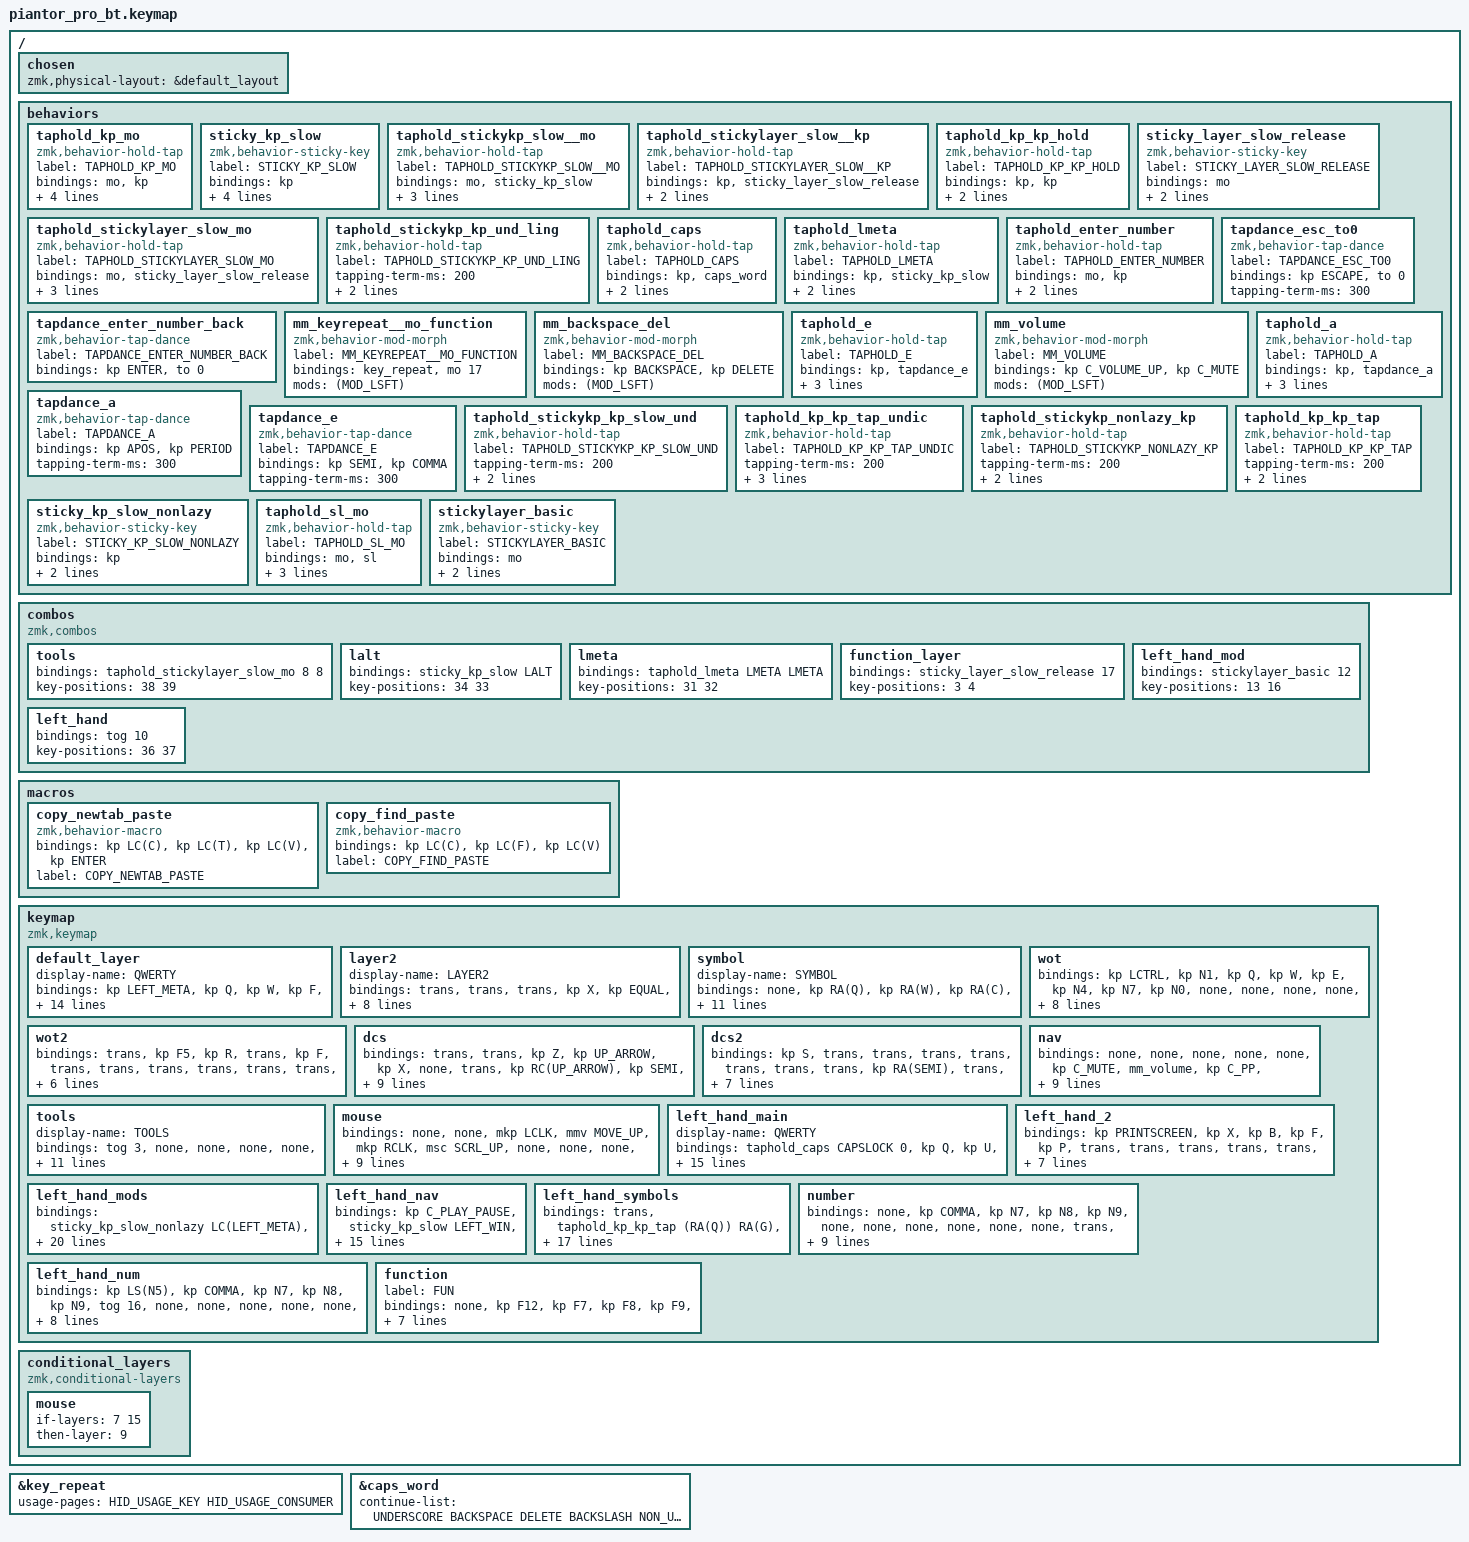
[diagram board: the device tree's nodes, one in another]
/*
 * Copyright (c) 2020 The ZMK Contributors
 *
 * SPDX-License-Identifier: MIT
 */

#include <behaviors.dtsi>
#include <dt-bindings/zmk/bt.h>
#include <dt-bindings/zmk/keys.h>
#include <dt-bindings/zmk/outputs.h>
#include <dt-bindings/zmk/pointing.h>
#include <dt-bindings/zmk/rgb.h>

&key_repeat { usage-pages = <HID_USAGE_KEY HID_USAGE_CONSUMER>; };

&caps_word { continue-list = <UNDERSCORE BACKSPACE DELETE BACKSLASH NON_US_BACKSLASH MINUS EQUAL APOSTROPHE LEFT_BRACKET RIGHT_BRACKET NUMBER_0 SEMICOLON>; };

/ {
    chosen { zmk,physical-layout = &default_layout; };
};

/ {
    behaviors {
        taphold_kp_mo: taphold_kp_mo {
            compatible = "zmk,behavior-hold-tap";
            label = "TAPHOLD_KP_MO";
            bindings = <&mo>, <&kp>;

            #binding-cells = <2>;
            hold-while-undecided;
            hold-trigger-on-release;
            flavor = "balanced";
            tapping-term-ms = <200>;
        };

        sticky_kp_slow: sticky_kp_slow {
            compatible = "zmk,behavior-sticky-key";
            label = "STICKY_KP_SLOW";
            bindings = <&kp>;
            #binding-cells = <1>;
            release-after-ms = <2000>;
            lazy;
            ignore-modifiers;
            quick-release;
        };

        taphold_stickykp_slow__mo: taphold_stickykp_slow__mo {
            compatible = "zmk,behavior-hold-tap";
            label = "TAPHOLD_STICKYKP_SLOW__MO";
            bindings = <&mo>, <&sticky_kp_slow>;

            #binding-cells = <2>;
            hold-while-undecided;
            flavor = "hold-preferred";
            tapping-term-ms = <200>;
        };

        taphold_stickylayer_slow__kp: taphold_stickylayer_slow__kp {
            compatible = "zmk,behavior-hold-tap";
            label = "TAPHOLD_STICKYLAYER_SLOW__KP";
            bindings = <&kp>, <&sticky_layer_slow_release>;

            #binding-cells = <2>;
            tapping-term-ms = <200>;
            flavor = "balanced";
        };

        taphold_kp_kp_hold: taphold_kp_kp_hold {
            compatible = "zmk,behavior-hold-tap";
            label = "TAPHOLD_KP_KP_HOLD";
            bindings = <&kp>, <&kp>;

            #binding-cells = <2>;
            flavor = "hold-preferred";
            tapping-term-ms = <230>;
        };

        sticky_layer_slow_release: sticky_layer_slow_release {
            compatible = "zmk,behavior-sticky-key";
            label = "STICKY_LAYER_SLOW_RELEASE";
            bindings = <&mo>;
            #binding-cells = <1>;
            release-after-ms = <1000>;
            ignore-modifiers;
        };

        taphold_stickylayer_slow_mo: taphold_stickylayer_slow_mo {
            compatible = "zmk,behavior-hold-tap";
            label = "TAPHOLD_STICKYLAYER_SLOW_MO";
            bindings = <&mo>, <&sticky_layer_slow_release>;

            #binding-cells = <2>;
            flavor = "balanced";
            hold-while-undecided;
            tapping-term-ms = <200>;
        };

        taphold_stickykp_kp_und_ling: taphold_stickykp_kp_und_ling {
            compatible = "zmk,behavior-hold-tap";
            label = "TAPHOLD_STICKYKP_KP_UND_LING";
            #binding-cells = <2>;
            tapping-term-ms = <200>;
            bindings = <&kp>, <&sticky_kp_slow>;

            hold-while-undecided-linger;
        };

        taphold_caps: taphold_caps {
            compatible = "zmk,behavior-hold-tap";
            label = "TAPHOLD_CAPS";
            bindings = <&kp>, <&caps_word>;

            #binding-cells = <2>;
            tapping-term-ms = <200>;
            flavor = "tap-preferred";
        };

        taphold_lmeta: taphold_lmeta {
            compatible = "zmk,behavior-hold-tap";
            label = "TAPHOLD_LMETA";
            bindings = <&kp>, <&sticky_kp_slow>;

            #binding-cells = <2>;
            tapping-term-ms = <200>;
            flavor = "balanced";
        };

        taphold_enter_number: taphold_enter_number {
            compatible = "zmk,behavior-hold-tap";
            label = "TAPHOLD_ENTER_NUMBER";
            bindings = <&mo>, <&kp>;

            #binding-cells = <2>;
            tapping-term-ms = <200>;
            flavor = "balanced";
        };

        tapdance_enter_number_back: tapdance_enter_number_back {
            compatible = "zmk,behavior-tap-dance";
            label = "TAPDANCE_ENTER_NUMBER_BACK";
            #binding-cells = <0>;
            bindings = <&kp ENTER>, <&to 0>;
        };

        mm_keyrepeat__mo_function: mm_keyrepeat__mo_function {
            compatible = "zmk,behavior-mod-morph";
            label = "MM_KEYREPEAT__MO_FUNCTION";
            bindings = <&key_repeat>, <&mo 17>;

            #binding-cells = <0>;
            mods = <(MOD_LSFT)>;
        };

        mm_backspace_del: mm_backspace_del {
            compatible = "zmk,behavior-mod-morph";
            label = "MM_BACKSPACE_DEL";
            bindings = <&kp BACKSPACE>, <&kp DELETE>;

            #binding-cells = <0>;
            mods = <(MOD_LSFT)>;
        };

        tapdance_esc_to0: tapdance_esc_to0 {
            compatible = "zmk,behavior-tap-dance";
            label = "TAPDANCE_ESC_TO0";
            #binding-cells = <0>;
            bindings = <&kp ESCAPE>, <&to 0>;

            tapping-term-ms = <300>;
        };

        taphold_e: taphold_e {
            compatible = "zmk,behavior-hold-tap";
            label = "TAPHOLD_E";
            bindings = <&kp>, <&tapdance_e>;

            #binding-cells = <2>;
            flavor = "tap-preferred";
            tapping-term-ms = <170>;
            quick-tap-ms = <169>;
        };

        mm_volume: mm_volume {
            compatible = "zmk,behavior-mod-morph";
            label = "MM_VOLUME";
            bindings = <&kp C_VOLUME_UP>, <&kp C_MUTE>;

            #binding-cells = <0>;
            mods = <(MOD_LSFT)>;
        };

        tapdance_a: tapdance_a {
            compatible = "zmk,behavior-tap-dance";
            label = "TAPDANCE_A";
            #binding-cells = <0>;
            bindings = <&kp APOS>, <&kp PERIOD>;

            tapping-term-ms = <300>;
        };

        tapdance_e: tapdance_e {
            compatible = "zmk,behavior-tap-dance";
            label = "TAPDANCE_E";
            #binding-cells = <0>;
            bindings = <&kp SEMI>, <&kp COMMA>;

            tapping-term-ms = <300>;
        };

        taphold_a: taphold_a {
            compatible = "zmk,behavior-hold-tap";
            label = "TAPHOLD_A";
            bindings = <&kp>, <&tapdance_a>;

            #binding-cells = <2>;
            flavor = "tap-preferred";
            tapping-term-ms = <170>;
            quick-tap-ms = <169>;
        };

        taphold_stickykp_kp_slow_und: taphold_stickykp_kp_slow_und {
            compatible = "zmk,behavior-hold-tap";
            label = "TAPHOLD_STICKYKP_KP_SLOW_UND";
            #binding-cells = <2>;
            tapping-term-ms = <200>;
            bindings = <&kp>, <&sticky_kp_slow>;

            hold-while-undecided;
        };

        taphold_kp_kp_tap_undic: taphold_kp_kp_tap_undic {
            compatible = "zmk,behavior-hold-tap";
            label = "TAPHOLD_KP_KP_TAP_UNDIC";
            #binding-cells = <2>;
            tapping-term-ms = <200>;
            bindings = <&kp>, <&kp>;

            hold-while-undecided;
            flavor = "tap-preferred";
        };

        taphold_stickykp_nonlazy_kp: taphold_stickykp_nonlazy_kp {
            compatible = "zmk,behavior-hold-tap";
            label = "TAPHOLD_STICKYKP_NONLAZY_KP";
            #binding-cells = <2>;
            tapping-term-ms = <200>;
            bindings = <&kp>, <&sticky_kp_slow_nonlazy>;

            flavor = "tap-preferred";
        };

        taphold_kp_kp_tap: taphold_kp_kp_tap {
            compatible = "zmk,behavior-hold-tap";
            label = "TAPHOLD_KP_KP_TAP";
            #binding-cells = <2>;
            tapping-term-ms = <200>;
            bindings = <&kp>, <&kp>;

            flavor = "tap-preferred";
        };

        sticky_kp_slow_nonlazy: sticky_kp_slow_nonlazy {
            compatible = "zmk,behavior-sticky-key";
            label = "STICKY_KP_SLOW_NONLAZY";
            bindings = <&kp>;
            #binding-cells = <1>;
            release-after-ms = <2000>;
            ignore-modifiers;
        };

        taphold_sl_mo: taphold_sl_mo {
            compatible = "zmk,behavior-hold-tap";
            label = "TAPHOLD_SL_MO";
            bindings = <&mo>, <&sl>;

            #binding-cells = <2>;
            flavor = "balanced";
            hold-while-undecided;
            tapping-term-ms = <200>;
        };

        stickylayer_basic: stickylayer_basic {
            compatible = "zmk,behavior-sticky-key";
            label = "STICKYLAYER_BASIC";
            bindings = <&mo>;
            #binding-cells = <1>;
            release-after-ms = <2000>;
            quick-release;
        };
    };

    combos {
        compatible = "zmk,combos";

        tools {
            bindings = <&taphold_stickylayer_slow_mo 8 8>;
            key-positions = <38 39>;
        };

        lalt {
            bindings = <&sticky_kp_slow LALT>;
            key-positions = <34 33>;
        };

        lmeta {
            bindings = <&taphold_lmeta LMETA LMETA>;
            key-positions = <31 32>;
        };

        function_layer {
            bindings = <&sticky_layer_slow_release 17>;
            key-positions = <3 4>;
        };

        left_hand_mod {
            bindings = <&stickylayer_basic 12>;
            key-positions = <13 16>;
        };

        left_hand {
            bindings = <&tog 10>;
            key-positions = <36 37>;
        };
    };

    macros {
        copy_newtab_paste: copy_newtab_paste {
            compatible = "zmk,behavior-macro";
            #binding-cells = <0>;
            bindings = <&kp LC(C) &kp LC(T) &kp LC(V) &kp ENTER>;
            label = "COPY_NEWTAB_PASTE";
        };

        copy_find_paste: copy_find_paste {
            compatible = "zmk,behavior-macro";
            #binding-cells = <0>;
            bindings = <&kp LC(C) &kp LC(F) &kp LC(V)>;
            label = "COPY_FIND_PASTE";
        };
    };

    keymap {
        compatible = "zmk,keymap";

        default_layer {
            display-name = "QWERTY";

            // --------------------------------------------------------------------------------
            // |  TAB |  Q  |  W  |  E  |  R  |  T  |  Y  |  U   |  I  |  O  |  P  | BSPC |
            // | CTRL |  A  |  S  |  D  |  F  |  G  |  H  |  J   |  K  |  L  |  ;  |  '   |
            // | SHFT |  Z  |  X  |  C  |  V  |  B  |  N  |  M   |  ,  |  .  |  /  | ESC  |
            //                    | GUI | LWR | SPC | ENT | RSE  | ALT |

            bindings = <
&kp LEFT_META  &kp Q  &kp W  &kp F  &kp P  &kp B  &kp J  &kp L  &kp O  &kp U  &kp DEL  &kp PRINTSCREEN  &mm_backspace_del  &kp K  &kp R  &kp S  &kp T  &kp G  &kp M  &kp N  &kp E  &kp I  &kp A  &kp TAB  &taphold_kp_kp_hold LCTRL ESCAPE  &kp Z  &kp Y  &kp C  &kp D  &kp V  &kp X  &kp H  &taphold_e COMMA SEMI  &taphold_a PERIOD APOS  &kp SLASH  &taphold_caps CAPSLOCK LGUI  &taphold_stickykp_slow__mo 7 LCTRL  &taphold_kp_mo 2 SPACE  &taphold_stickykp_kp_und_ling LSHIFT LSHIFT  &mm_keyrepeat__mo_function  &taphold_stickylayer_slow_mo 1 1  &taphold_enter_number 15 ENTER
            >;
        };

        layer2 {
            display-name = "LAYER2";

            // -----------------------------------------------------------------------------------------
            // |  TAB |  !  |  @  |  #  |  $  |  %  |  ^  |  &  |  *  |  (  |  )  | BSPC |
            // | CTRL | HUD | HUI |     |     |     |  -  |  =  |  [  |  ]  |  \  |  `   |
            // | SHFT |     |     |     |     |     |  _  |  +  |  {  |  }  | "|" |  ~   |
            //                    | GUI |     | SPC | ENT |     | ALT |

            bindings = <
&trans  &trans  &trans  &kp X  &kp EQUAL  &trans  &trans  &trans  &kp N0  &kp MINUS  &trans  &trans  &trans  &trans  &trans  &trans  &kp J  &kp RIGHT_BRACKET  &trans  &trans  &trans  &trans  &trans  &kp NON_US_BACKSLASH  &trans  &trans  &trans  &kp V  &kp B  &trans  &trans  &trans  &kp LEFT_BRACKET  &kp BACKSLASH  &trans  &trans  &trans  &trans  &trans  &trans  &trans  &trans
            >;
        };

        symbol {
            display-name = "SYMBOL";

            // -----------------------------------------------------------------------------------------
            // |  TAB |  1  |  2  |  3  |  4  |  5    |  6  |  7  |  8  |  9  |  0  | BSPC |
            // | CTRL | BT1 | BT2 | BT3 | BT4 | BT5   | LFT | DWN |  UP | RGT |     |      |
            // | SHFT | BTCR| RGB | RST | BOOT| Unlock|     |     |     |     |     |      |
            //                    | GUI |     | SPC   | ENT |     | ALT |

            bindings = <
&none  &kp RA(Q)  &kp RA(W)  &kp RA(C)  &kp RA(N7)  &none  &none  &kp LS(N9)  &kp RA(N)  &kp RA(Z)  &kp RA(G)  &none  &trans  &kp RA(NUMBER_1)  &kp LS(NUMBER_4)  &kp LS(N7)  &kp RA(COMMA)  &kp LS(NUMBER_1)  &kp LS(NUMBER_2)  &kp LS(N8)  &kp RA(B)  &kp RA(NON_US_BACKSLASH)  &kp RA(F)  &none  &none  &kp RA(NUMBER_3)  &kp RA(SEMI)  &kp RA(X)  &kp RA(V)  &none  &none  &kp LS(NUMBER_6)  &kp RA(SLASH)  &kp LS(NUMBER_3)  &kp LS(N5)  &none  &trans  &trans  &trans  &trans  &trans  &trans
            >;
        };

        wot {
            bindings = <
&kp LCTRL  &kp N1  &kp Q  &kp W  &kp E  &kp N4  &kp N7  &kp N0  &none  &none  &none  &none  &kp TAB  &kp N2  &kp A  &kp S  &kp D  &kp N5  &kp N8  &none  &none  &none  &none  &none  &tapdance_esc_to0  &kp N3  &kp X  &kp C  &kp V  &kp N6  &kp N9  &none  &none  &none  &none  &none  &mo 4  &kp SPACE  &taphold_kp_kp_hold LEFT_SHIFT ENTER  &none  &mo 0  &to 0
            >;

            label = "WOT";
        };

        wot2 {
            bindings = <
&trans  &kp F5  &kp R  &trans  &kp F  &trans  &trans  &trans  &trans  &trans  &trans  &trans  &kp F6  &kp F7  &trans  &trans  &trans  &trans  &trans  &trans  &trans  &trans  &trans  &trans  &trans  &kp F8  &kp Y  &trans  &trans  &trans  &trans  &trans  &trans  &trans  &trans  &trans  &trans  &trans  &trans  &trans  &trans  &trans
            >;
        };

        dcs {
            bindings = <
&trans  &trans  &kp Z  &kp UP_ARROW  &kp X  &none  &trans  &kp RC(UP_ARROW)  &kp SEMI  &kp RC(DOWN)  &trans  &kp BACKSLASH  &trans  &taphold_kp_kp_hold (LS(B)) LC(B)  &kp LEFT_ARROW  &kp DOWN  &kp RIGHT  &kp NUMBER_3  &trans  &kp COMMA  &kp PERIOD  &kp SLASH  &trans  &trans  &tapdance_esc_to0  &trans  &kp RS(PAGE_DOWN)  &kp LA(C)  &kp RS(PG_UP)  &none  &trans  &kp RC(LEFT)  &kp C  &kp RC(RIGHT)  &trans  &trans  &kp SPACE  &trans  &kp RA(SPACE)  &trans  &mo 6  &kp ENTER
            >;
        };

        dcs2 {
            bindings = <
&kp S  &trans  &trans  &trans  &trans  &trans  &trans  &trans  &kp RA(SEMI)  &trans  &trans  &kp LS(LC(F))  &kp RS(HOME)  &trans  &trans  &trans  &trans  &kp NUMBER_4  &trans  &kp RA(COMMA)  &kp RA(PERIOD)  &kp RA(SLASH)  &trans  &kp G  &kp RS(END)  &trans  &trans  &trans  &trans  &trans  &trans  &trans  &trans  &trans  &trans  &trans  &trans  &trans  &trans  &trans  &trans  &trans
            >;
        };

        nav {
            bindings = <
&none  &none  &none  &none  &none  &kp C_MUTE  &mm_volume  &kp C_PP  &kp C_PREVIOUS  &kp C_NEXT  &none  &none  &trans  &kp LGUI  &kp LALT  &kp LCTRL  &kp LSHFT  &none  &kp LEFT  &kp DOWN  &kp UP  &kp RIGHT  &kp PG_UP  &none  &tapdance_esc_to0  &none  &none  &none  &sticky_kp_slow LA(LC(LMETA))  &none  &kp C_VOLUME_DOWN  &kp HOME  &kp END  &kp PERIOD  &kp PAGE_DOWN  &none  &to 0  &trans  &trans  &trans  &trans  &trans
            >;

            label = "NAV";
        };

        tools {
            display-name = "TOOLS";
            bindings = <
&tog 3  &none  &none  &none  &none  &bt BT_CLR  &none  &rgb_ug RGB_TOG  &rgb_ug RGB_EFF  &rgb_ug RGB_BRD  &rgb_ug RGB_BRI  &none  &tog 5  &bt BT_SEL 0  &bt BT_SEL 1  &bt BT_SEL 2  &bt BT_SEL 3  &bt BT_SEL 4  &none  &kp C_PP  &kp C_PREVIOUS  &kp K_NEXT  &none  &none  &none  &studio_unlock  &none  &none  &out OUT_TOG  &none  &none  &rgb_ug RGB_HUD  &rgb_ug RGB_HUI  &rgb_ug RGB_SAD  &rgb_ug RGB_SAI  &rgb_ug RGB_COLOR_HSB(0,0,100)  &trans  &trans  &trans  &trans  &trans  &trans
            >;
        };

        mouse {
            bindings = <
&none  &none  &mkp LCLK  &mmv MOVE_UP  &mkp RCLK  &msc SCRL_UP  &none  &none  &none  &none  &none  &none  &msc SCRL_LEFT  &msc SCRL_RIGHT  &mmv MOVE_LEFT  &mmv MOVE_DOWN  &mmv MOVE_RIGHT  &msc SCRL_DOWN  &none  &kp LSHIFT  &kp LCTRL  &kp LALT  &kp LGUI  &none  &tapdance_esc_to0  &mkp LCLK  &mkp MB4  &mkp MCLK  &mkp MB5  &to 9  &none  &none  &none  &none  &none  &none  &trans  &trans  &trans  &trans  &trans  &trans
            >;

            label = "MOUSE";
        };

        left_hand_main {
            display-name = "QWERTY";
            bindings = <
&taphold_caps CAPSLOCK 0  &kp Q  &kp U  &kp I  &kp O  &tog 16  &trans  &trans  &trans  &trans  &trans  &to 0  &mm_backspace_del  &kp R  &taphold_kp_kp_tap SLASH T  &taphold_kp_kp_tap PERIOD N  &taphold_kp_kp_tap COMMA E  &kp K  &trans  &trans  &trans  &trans  &trans  &trans  &taphold_kp_kp_hold LCTRL ESCAPE  &taphold_kp_kp_tap LS(NUMBER_6) D  &taphold_kp_kp_tap RA(SLASH) S  &taphold_kp_kp_tap LS(NUMBER_3) H  &taphold_kp_kp_tap LS(N5) A  &key_repeat  &trans  &trans  &trans  &trans  &trans  &trans  &taphold_kp_mo 15 SPACE  &taphold_sl_mo 13 11  &taphold_stickylayer_slow__kp LEFT_SHIFT 14  &trans  &trans  &trans
            >;
        };

        left_hand_2 {
            bindings = <
&kp PRINTSCREEN  &kp X  &kp B  &kp F  &kp P  &trans  &trans  &trans  &trans  &trans  &trans  &trans  &kp TAB  &kp W  &kp M  &kp L  &kp J  &kp G  &trans  &trans  &trans  &trans  &trans  &trans  &trans  &kp Z  &kp Y  &kp C  &kp V  &trans  &trans  &trans  &trans  &trans  &trans  &trans  &kp ENTER  &sticky_kp_slow_nonlazy LEFT_CONTROL  &kp LEFT_SHIFT  &trans  &trans  &trans
            >;
        };

        left_hand_mods {
            bindings = <
&sticky_kp_slow_nonlazy LC(LEFT_META)  &sticky_kp_slow_nonlazy LS(LEFT_META)  &sticky_kp_slow_nonlazy LS(LEFT_ALT)  &sticky_kp_slow_nonlazy LC(LEFT_ALT)  &sticky_kp_slow_nonlazy LS(LEFT_CONTROL)  &sticky_kp_slow_nonlazy LA(LEFT_META)  &trans  &trans  &trans  &trans  &trans  &trans  &sticky_kp_slow_nonlazy LA(LS(LC(LEFT_META)))  &taphold_stickykp_nonlazy_kp LEFT_WIN LEFT_WIN  &taphold_stickykp_nonlazy_kp LEFT_ALT LEFT_ALT  &taphold_stickykp_nonlazy_kp LEFT_CONTROL LEFT_CONTROL  &taphold_stickykp_nonlazy_kp LEFT_SHIFT LEFT_SHIFT  &taphold_caps CAPSLOCK 0  &trans  &trans  &trans  &trans  &trans  &trans  &trans  &sticky_kp_slow_nonlazy LC(LS(LEFT_ALT))  &sticky_kp_slow_nonlazy LC(LS(LEFT_META))  &sticky_kp_slow_nonlazy LS(LA(LEFT_META))  &sticky_kp_slow_nonlazy LA(LC(LEFT_META))  &trans  &trans  &trans  &trans  &trans  &trans  &trans  &trans  &trans  &trans  &trans  &trans  &trans
            >;
        };

        left_hand_nav {
            bindings = <
&kp C_PLAY_PAUSE  &sticky_kp_slow LEFT_WIN  &sticky_kp_slow LEFT_ALT  &sticky_kp_slow LEFT_CONTROL  &sticky_kp_slow LEFT_SHIFT  &tog 13  &trans  &trans  &trans  &trans  &trans  &trans  &mm_volume  &kp LEFT_ARROW  &kp DOWN  &kp UP_ARROW  &kp RIGHT  &taphold_kp_kp_hold LEFT_CONTROL LEFT_CONTROL  &trans  &trans  &trans  &trans  &trans  &trans  &kp C_VOLUME_DOWN  &kp PAGE_DOWN  &kp PAGE_UP  &kp HOME  &kp END  &none  &trans  &trans  &trans  &trans  &trans  &trans  &taphold_stickykp_kp_und_ling LEFT_WIN LEFT_WIN  &taphold_stickykp_kp_und_ling LEFT_ALT LEFT_ALT  &taphold_stickykp_kp_und_ling LEFT_SHIFT LEFT_SHIFT  &trans  &trans  &trans
            >;
        };

        left_hand_symbols {
            bindings = <
&trans  &taphold_kp_kp_tap (RA(Q)) RA(G)  &taphold_kp_kp_tap (RA(W)) RA(Z)  &taphold_kp_kp_tap (RA(C)) RA(N)  &taphold_kp_kp_tap (RA(N7)) LS(N9)  &trans  &trans  &trans  &trans  &trans  &trans  &trans  &kp LS(NUMBER_1)  &taphold_kp_kp_tap (RA(NUMBER_1)) RA(F)  &taphold_kp_kp_tap (LS(NUMBER_4)) RA(NON_US_BSLH)  &taphold_kp_kp_tap (LS(N7)) RA(B)  &taphold_kp_kp_tap (RA(COMMA)) LS(N8)  &kp LS(NUMBER_2)  &trans  &trans  &trans  &trans  &trans  &trans  &trans  &taphold_kp_kp_tap (RA(NUMBER_3)) RA(N0)  &taphold_kp_kp_tap (RA(SEMI)) RA(MINUS)  &taphold_kp_kp_tap (RA(X)) RA(N9)  &kp RA(V)  &trans  &trans  &trans  &trans  &trans  &trans  &trans  &trans  &kp LS(N7)  &trans  &trans  &trans  &trans
            >;
        };

        number {
            bindings = <
&none  &kp COMMA  &kp N7  &kp N8  &kp N9  &none  &none  &none  &none  &none  &none  &trans  &trans  &kp GRAVE  &kp N4  &kp N5  &kp N6  &sticky_kp_slow LC(LMETA)  &none  &kp LSHFT  &kp LCTRL  &kp LALT  &kp LGUI  &none  &tapdance_esc_to0  &kp DOT  &kp N1  &kp N2  &kp N3  &none  &none  &kp LS(NUMBER_6)  &kp RA(SLASH)  &kp LS(NUMBER_3)  &kp SLASH  &kp LS(N7)  &trans  &trans  &trans  &trans  &trans  &tapdance_enter_number_back
            >;

            label = "NUM";
        };

        left_hand_num {
            bindings = <
&kp LS(N5)  &kp COMMA  &kp N7  &kp N8  &kp N9  &tog 16  &none  &none  &none  &none  &none  &trans  &kp LS(NUMBER_3)  &kp GRAVE  &kp N4  &kp N5  &kp N6  &kp RA(SLASH)  &none  &kp LSHFT  &kp LCTRL  &kp LALT  &kp LGUI  &none  &kp SLASH  &kp DOT  &kp N1  &kp N2  &kp N3  &kp LS(NUMBER_6)  &none  &kp LS(NUMBER_6)  &kp RA(SLASH)  &kp LS(NUMBER_3)  &kp SLASH  &kp LS(N7)  &kp ENTER  &kp SPACE  &kp LS(N7)  &trans  &trans  &tapdance_enter_number_back
            >;
        };

        function {
            label = "FUN";
            bindings = <
&none  &kp F12  &kp F7  &kp F8  &kp F9  &none  &kp C_VOLUME_UP  &kp C_PP  &kp C_PREV  &kp C_NEXT  &none  &trans  &trans  &kp F11  &kp F4  &kp F5  &kp F6  &none  &kp C_VOLUME_DOWN  &kp LSHFT  &kp LCTRL  &kp LALT  &kp LGUI  &none  &none  &kp F10  &kp F1  &kp F2  &kp F3  &none  &kp C_MUTE  &none  &none  &none  &none  &trans  &none  &none  &none  &none  &none  &none
            >;
        };
    };

    conditional_layers {
        compatible = "zmk,conditional-layers";

        mouse {
            if-layers = <7 15>;
            then-layer = <9>;
        };
    };
};
